# MKM34Z7 register map
Vendor: Freescale Semiconductor, Inc.; Series: Kinetis_M; File version: 1.6
CPU: CM0PLUS r0p0, little endian, no MPU, no FPU, VTOR, 2 interrupt priority bits
Registers are 32-bit, read-write, reset 0x0 unless marked. A register's access mark holds for its fields unless they carry their own. Offsets are from the block's base; [hi:lo] are bit positions; {n}, {i} and the like mark numbered series.

## NVIC — Nested Vectored Interrupt Controller
Base 0xE000E100
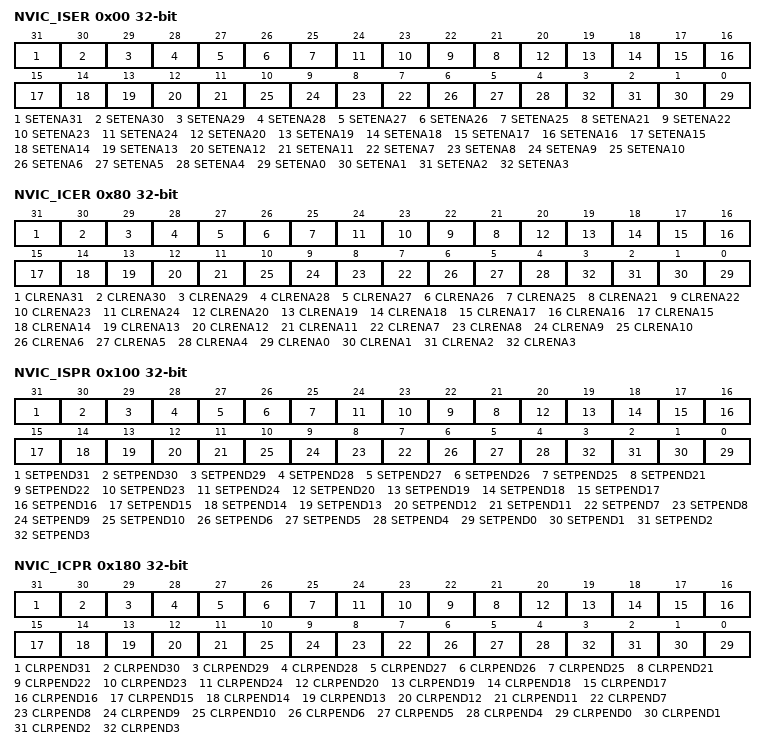
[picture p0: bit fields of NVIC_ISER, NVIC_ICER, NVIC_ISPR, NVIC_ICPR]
0x00 NVIC_ISER — Interrupt Set Enable Register
  [31] SETENA31 — XBAR interrupt set-enable bit
    0=write: no effect; read: XBAR interrupt disabled; 1=write: enable XBAR interrupt; read: XBAR interrupt enabled
  [30] SETENA30 — Low-Power Timer interrupt set-enable bit
    0=write: no effect; read: Low-Power Timer interrupt disabled; 1=write: enable Low-Power Timer interrupt; read: Low-Power Timer interrupt enabled
  [29] SETENA29 — EWM/WDOG interrupt set-enable bit
    0=write: no effect; read: EWM/WDOG interrupt disabled; 1=write: enable EWM/WDOG interrupt; read: EWM/WDOG interrupt enabled
  [28] SETENA28 — Multipurpose Clock Generator interrupt set-enable bit
    0=write: no effect; read: Multipurpose Clock Generator interrupt disabled; 1=write: enable Multipurpose Clock Generator interrupt; read: Multipurpose Clock Generator interrupt enabled
  [27] SETENA27 — LPUART0 status and error interrupt set-enable bit
    0=write: no effect; read: LPUART0 status and error interrupt disabled; 1=write: enable LPUART0 status and error interrupt; read: LPUART0 status and error interrupt enabled
  [26] SETENA26 — I2C0/I2C1 interrupt set-enable bit
    0=write: no effect; read: I2C0/I2C1 interrupt disabled; 1=write: enable I2C0/I2C1 interrupt; read: I2C0/I2C1 interrupt enabled
  [25] SETENA25 — IRTC interrupt interrupt set-enable bit
    0=write: no effect; read: IRTC interrupt interrupt disabled; 1=write: enable IRTC interrupt interrupt; read: IRTC interrupt interrupt enabled
  [n] SETENA{n} (n=21..24) — AFE Channel {n-21} interrupt set-enable bit
    0=write: no effect; read: AFE Channel {n-21} interrupt disabled; 1=write: enable AFE Channel {n-21} interrupt; read: AFE Channel {n-21} interrupt enabled
  [20] SETENA20 — Memory Mapped Arithmetic Unit interrupt set-enable bit
    0=write: no effect; read: Memory Mapped Arithmetic Unit interrupt disabled; 1=write: enable Memory Mapped Arithmetic Unit interrupt; read: Memory Mapped Arithmetic Unit interrupt enabled
  [19] SETENA19 — UART0/UART1/UART2/UART3 interrupt set-enable bit
    0=write: no effect; read: UART0/UART1/UART2/UART3 interrupt disabled; 1=write: enable UART0/UART1/UART2/UART3 interrupt; read: UART0/UART1/UART2/UART3 interrupt enabled
  [18] SETENA18 — RNGA interrupt set-enable bit
    0=write: no effect; read: RNGA interrupt disabled; 1=write: enable RNGA interrupt; read: RNGA interrupt enabled
  [17] SETENA17 — PORTA,PORTB,PORTC,PORTD,PORTE,PORTF,PORTH,PORTI,PORTJ,PORTK,PORTL,PORTM interrupt set-enable bit
    0=write: no effect; read: PORTA,PORTB,PORTC,PORTD,PORTE,PORTF,PORTH,PORTI,PORTJ,PORTK,PORTL,PORTM interrupt disabled; 1=write: enable PORTA,PORTB,PORTC,PORTD,PORTE,PORTF,PORTH,PORTI,PORTJ,PORTK,PORTL,PORTM interrupt; read: PORTA,PORTB,PORTC,PORTD,PORTE,PORTF,PORTH,PORTI,PORTJ,PORTK,PORTL,PORTM interrupt enabled
  [16] SETENA16 — Analog-to-Digital Converter interrupt set-enable bit
    0=write: no effect; read: Analog-to-Digital Converter interrupt disabled; 1=write: enable Analog-to-Digital Converter interrupt; read: Analog-to-Digital Converter interrupt enabled
  [15] SETENA15 — Segment LCD interrupt set-enable bit
    0=write: no effect; read: Segment LCD interrupt disabled; 1=write: enable Segment LCD interrupt; read: Segment LCD interrupt enabled
  [14] SETENA14 — CMP0/CMP1/CMP2 interrupt set-enable bit
    0=write: no effect; read: CMP0/CMP1/CMP2 interrupt disabled; 1=write: enable CMP0/CMP1/CMP2 interrupt; read: CMP0/CMP1/CMP2 interrupt enabled
  [13] SETENA13 — Command complete and read collision interrupt set-enable bit
    0=write: no effect; read: Command complete and read collision interrupt disabled; 1=write: enable Command complete and read collision interrupt; read: Command complete and read collision interrupt enabled
  [12] SETENA12 — Low Leakage Wakeup interrupt set-enable bit
    0=write: no effect; read: Low Leakage Wakeup interrupt disabled; 1=write: enable Low Leakage Wakeup interrupt; read: Low Leakage Wakeup interrupt enabled
  [11] SETENA11 — PIT0/PIT1 interrupt set-enable bit
    0=write: no effect; read: PIT0/PIT1 interrupt disabled; 1=write: enable PIT0/PIT1 interrupt; read: PIT0/PIT1 interrupt enabled
  [n] SETENA{n} (n=7..10) — Quad Timer Channel {n-7} interrupt set-enable bit
    0=write: no effect; read: Quad Timer Channel {n-7} interrupt disabled; 1=write: enable Quad Timer Channel {n-7} interrupt; read: Quad Timer Channel {n-7} interrupt enabled
  [6] SETENA6 — Low-voltage detect, low-voltage warning interrupt set-enable bit
    0=write: no effect; read: Low-voltage detect, low-voltage warning interrupt disabled; 1=write: enable Low-voltage detect, low-voltage warning interrupt; read: Low-voltage detect, low-voltage warning interrupt enabled
  [5] SETENA5 — Programmable Delay Block 0 interrupt set-enable bit
    0=write: no effect; read: Programmable Delay Block 0 interrupt disabled; 1=write: enable Programmable Delay Block 0 interrupt; read: Programmable Delay Block 0 interrupt enabled
  [4] SETENA4 — Serial Peripheral Interface 0/1 interrupt set-enable bit
    0=write: no effect; read: Serial Peripheral Interface 0/1 interrupt disabled; 1=write: enable Serial Peripheral Interface 0/1 interrupt; read: Serial Peripheral Interface 0/1 interrupt enabled
  [n] SETENA{n} (n=0..3) — DMA channel {n} transfer complete interrupt set-enable bit
    0=write: no effect; read: DMA channel {n} transfer complete interrupt disabled; 1=write: enable DMA channel {n} transfer complete interrupt; read: DMA channel {n} transfer complete interrupt enabled
0x80 NVIC_ICER — Interrupt Clear Enable Register
  [31] CLRENA31 — XBAR interrupt clear-enable bit
    0=write: no effect; read: XBAR interrupt disabled; 1=write: disable XBAR interrupt; read: XBAR interrupt enabled
  [30] CLRENA30 — Low-Power Timer interrupt clear-enable bit
    0=write: no effect; read: Low-Power Timer interrupt disabled; 1=write: disable Low-Power Timer interrupt; read: Low-Power Timer interrupt enabled
  [29] CLRENA29 — EWM/WDOG interrupt clear-enable bit
    0=write: no effect; read: EWM/WDOG interrupt disabled; 1=write: disable EWM/WDOG interrupt; read: EWM/WDOG interrupt enabled
  [28] CLRENA28 — Multipurpose Clock Generator interrupt clear-enable bit
    0=write: no effect; read: Multipurpose Clock Generator interrupt disabled; 1=write: disable Multipurpose Clock Generator interrupt; read: Multipurpose Clock Generator interrupt enabled
  [27] CLRENA27 — LPUART0 status and error interrupt clear-enable bit
    0=write: no effect; read: LPUART0 status and error interrupt disabled; 1=write: disable LPUART0 status and error interrupt; read: LPUART0 status and error interrupt enabled
  [26] CLRENA26 — I2C0/I2C1 interrupt clear-enable bit
    0=write: no effect; read: I2C0/I2C1 interrupt disabled; 1=write: disable I2C0/I2C1 interrupt; read: I2C0/I2C1 interrupt enabled
  [25] CLRENA25 — IRTC interrupt interrupt clear-enable bit
    0=write: no effect; read: IRTC interrupt interrupt disabled; 1=write: disable IRTC interrupt interrupt; read: IRTC interrupt interrupt enabled
  [n] CLRENA{n} (n=21..24) — AFE Channel {n-21} interrupt clear-enable bit
    0=write: no effect; read: AFE Channel {n-21} interrupt disabled; 1=write: disable AFE Channel {n-21} interrupt; read: AFE Channel {n-21} interrupt enabled
  [20] CLRENA20 — Memory Mapped Arithmetic Unit interrupt clear-enable bit
    0=write: no effect; read: Memory Mapped Arithmetic Unit interrupt disabled; 1=write: disable Memory Mapped Arithmetic Unit interrupt; read: Memory Mapped Arithmetic Unit interrupt enabled
  [19] CLRENA19 — UART0/UART1/UART2/UART3 interrupt clear-enable bit
    0=write: no effect; read: UART0/UART1/UART2/UART3 interrupt disabled; 1=write: disable UART0/UART1/UART2/UART3 interrupt; read: UART0/UART1/UART2/UART3 interrupt enabled
  [18] CLRENA18 — RNGA interrupt clear-enable bit
    0=write: no effect; read: RNGA interrupt disabled; 1=write: disable RNGA interrupt; read: RNGA interrupt enabled
  [17] CLRENA17 — PORTA,PORTB,PORTC,PORTD,PORTE,PORTF,PORTH,PORTI,PORTJ,PORTK,PORTL,PORTM interrupt clear-enable bit
    0=write: no effect; read: PORTA,PORTB,PORTC,PORTD,PORTE,PORTF,PORTH,PORTI,PORTJ,PORTK,PORTL,PORTM interrupt disabled; 1=write: disable PORTA,PORTB,PORTC,PORTD,PORTE,PORTF,PORTH,PORTI,PORTJ,PORTK,PORTL,PORTM interrupt; read: PORTA,PORTB,PORTC,PORTD,PORTE,PORTF,PORTH,PORTI,PORTJ,PORTK,PORTL,PORTM interrupt enabled
  [16] CLRENA16 — Analog-to-Digital Converter interrupt clear-enable bit
    0=write: no effect; read: Analog-to-Digital Converter interrupt disabled; 1=write: disable Analog-to-Digital Converter interrupt; read: Analog-to-Digital Converter interrupt enabled
  [15] CLRENA15 — Segment LCD interrupt clear-enable bit
    0=write: no effect; read: Segment LCD interrupt disabled; 1=write: disable Segment LCD interrupt; read: Segment LCD interrupt enabled
  [14] CLRENA14 — CMP0/CMP1/CMP2 interrupt clear-enable bit
    0=write: no effect; read: CMP0/CMP1/CMP2 interrupt disabled; 1=write: disable CMP0/CMP1/CMP2 interrupt; read: CMP0/CMP1/CMP2 interrupt enabled
  [13] CLRENA13 — Command complete and read collision interrupt clear-enable bit
    0=write: no effect; read: Command complete and read collision interrupt disabled; 1=write: disable Command complete and read collision interrupt; read: Command complete and read collision interrupt enabled
  [12] CLRENA12 — Low Leakage Wakeup interrupt clear-enable bit
    0=write: no effect; read: Low Leakage Wakeup interrupt disabled; 1=write: disable Low Leakage Wakeup interrupt; read: Low Leakage Wakeup interrupt enabled
  [11] CLRENA11 — PIT0/PIT1 interrupt clear-enable bit
    0=write: no effect; read: PIT0/PIT1 interrupt disabled; 1=write: disable PIT0/PIT1 interrupt; read: PIT0/PIT1 interrupt enabled
  [n] CLRENA{n} (n=7..10) — Quad Timer Channel {n-7} interrupt clear-enable bit
    0=write: no effect; read: Quad Timer Channel {n-7} interrupt disabled; 1=write: disable Quad Timer Channel {n-7} interrupt; read: Quad Timer Channel {n-7} interrupt enabled
  [6] CLRENA6 — Low-voltage detect, low-voltage warning interrupt clear-enable bit
    0=write: no effect; read: Low-voltage detect, low-voltage warning interrupt disabled; 1=write: disable Low-voltage detect, low-voltage warning interrupt; read: Low-voltage detect, low-voltage warning interrupt enabled
  [5] CLRENA5 — Programmable Delay Block 0 interrupt clear-enable bit
    0=write: no effect; read: Programmable Delay Block 0 interrupt disabled; 1=write: disable Programmable Delay Block 0 interrupt; read: Programmable Delay Block 0 interrupt enabled
  [4] CLRENA4 — Serial Peripheral Interface 0/1 interrupt clear-enable bit
    0=write: no effect; read: Serial Peripheral Interface 0/1 interrupt disabled; 1=write: disable Serial Peripheral Interface 0/1 interrupt; read: Serial Peripheral Interface 0/1 interrupt enabled
  [n] CLRENA{n} (n=0..3) — DMA channel {n} transfer complete interrupt clear-enable bit
    0=write: no effect; read: DMA channel {n} transfer complete interrupt disabled; 1=write: disable DMA channel {n} transfer complete interrupt; read: DMA channel {n} transfer complete interrupt enabled
0x100 NVIC_ISPR — Interrupt Set Pending Register
  [31] SETPEND31 — XBAR interrupt set-pending bit
    0=write: no effect; read: XBAR interrupt is not pending; 1=write: changes the XBAR interrupt state to pending; read: XBAR interrupt is pending
  [30] SETPEND30 — Low-Power Timer interrupt set-pending bit
    0=write: no effect; read: Low-Power Timer interrupt is not pending; 1=write: changes the Low-Power Timer interrupt state to pending; read: Low-Power Timer interrupt is pending
  [29] SETPEND29 — EWM/WDOG interrupt set-pending bit
    0=write: no effect; read: EWM/WDOG interrupt is not pending; 1=write: changes the EWM/WDOG interrupt state to pending; read: EWM/WDOG interrupt is pending
  [28] SETPEND28 — Multipurpose Clock Generator interrupt set-pending bit
    0=write: no effect; read: Multipurpose Clock Generator interrupt is not pending; 1=write: changes the Multipurpose Clock Generator interrupt state to pending; read: Multipurpose Clock Generator interrupt is pending
  [27] SETPEND27 — LPUART0 status and error interrupt set-pending bit
    0=write: no effect; read: LPUART0 status and error interrupt is not pending; 1=write: changes the LPUART0 status and error interrupt state to pending; read: LPUART0 status and error interrupt is pending
  [26] SETPEND26 — I2C0/I2C1 interrupt set-pending bit
    0=write: no effect; read: I2C0/I2C1 interrupt is not pending; 1=write: changes the I2C0/I2C1 interrupt state to pending; read: I2C0/I2C1 interrupt is pending
  [25] SETPEND25 — IRTC interrupt interrupt set-pending bit
    0=write: no effect; read: IRTC interrupt interrupt is not pending; 1=write: changes the IRTC interrupt interrupt state to pending; read: IRTC interrupt interrupt is pending
  [n] SETPEND{n} (n=21..24) — AFE Channel {n-21} interrupt set-pending bit
    0=write: no effect; read: AFE Channel {n-21} interrupt is not pending; 1=write: changes the AFE Channel {n-21} interrupt state to pending; read: AFE Channel {n-21} interrupt is pending
  [20] SETPEND20 — Memory Mapped Arithmetic Unit interrupt set-pending bit
    0=write: no effect; read: Memory Mapped Arithmetic Unit interrupt is not pending; 1=write: changes the Memory Mapped Arithmetic Unit interrupt state to pending; read: Memory Mapped Arithmetic Unit interrupt is pending
  [19] SETPEND19 — UART0/UART1/UART2/UART3 interrupt set-pending bit
    0=write: no effect; read: UART0/UART1/UART2/UART3 interrupt is not pending; 1=write: changes the UART0/UART1/UART2/UART3 interrupt state to pending; read: UART0/UART1/UART2/UART3 interrupt is pending
  [18] SETPEND18 — RNGA interrupt set-pending bit
    0=write: no effect; read: RNGA interrupt is not pending; 1=write: changes the RNGA interrupt state to pending; read: RNGA interrupt is pending
  [17] SETPEND17 — PORTA,PORTB,PORTC,PORTD,PORTE,PORTF,PORTH,PORTI,PORTJ,PORTK,PORTL,PORTM interrupt set-pending bit
    0=write: no effect; read: PORTA,PORTB,PORTC,PORTD,PORTE,PORTF,PORTH,PORTI,PORTJ,PORTK,PORTL,PORTM interrupt is not pending; 1=write: changes the PORTA,PORTB,PORTC,PORTD,PORTE,PORTF,PORTH,PORTI,PORTJ,PORTK,PORTL,PORTM interrupt state to pending; read: PORTA,PORTB,PORTC,PORTD,PORTE,PORTF,PORTH,PORTI,PORTJ,PORTK,PORTL,PORTM interrupt is pending
  [16] SETPEND16 — Analog-to-Digital Converter interrupt set-pending bit
    0=write: no effect; read: Analog-to-Digital Converter interrupt is not pending; 1=write: changes the Analog-to-Digital Converter interrupt state to pending; read: Analog-to-Digital Converter interrupt is pending
  [15] SETPEND15 — Segment LCD interrupt set-pending bit
    0=write: no effect; read: Segment LCD interrupt is not pending; 1=write: changes the Segment LCD interrupt state to pending; read: Segment LCD interrupt is pending
  [14] SETPEND14 — CMP0/CMP1/CMP2 interrupt set-pending bit
    0=write: no effect; read: CMP0/CMP1/CMP2 interrupt is not pending; 1=write: changes the CMP0/CMP1/CMP2 interrupt state to pending; read: CMP0/CMP1/CMP2 interrupt is pending
  [13] SETPEND13 — Command complete and read collision interrupt set-pending bit
    0=write: no effect; read: Command complete and read collision interrupt is not pending; 1=write: changes the Command complete and read collision interrupt state to pending; read: Command complete and read collision interrupt is pending
  [12] SETPEND12 — Low Leakage Wakeup interrupt set-pending bit
    0=write: no effect; read: Low Leakage Wakeup interrupt is not pending; 1=write: changes the Low Leakage Wakeup interrupt state to pending; read: Low Leakage Wakeup interrupt is pending
  [11] SETPEND11 — PIT0/PIT1 interrupt set-pending bit
    0=write: no effect; read: PIT0/PIT1 interrupt is not pending; 1=write: changes the PIT0/PIT1 interrupt state to pending; read: PIT0/PIT1 interrupt is pending
  [n] SETPEND{n} (n=7..10) — Quad Timer Channel {n-7} interrupt set-pending bit
    0=write: no effect; read: Quad Timer Channel {n-7} interrupt is not pending; 1=write: changes the Quad Timer Channel {n-7} interrupt state to pending; read: Quad Timer Channel {n-7} interrupt is pending
  [6] SETPEND6 — Low-voltage detect, low-voltage warning interrupt set-pending bit
    0=write: no effect; read: Low-voltage detect, low-voltage warning interrupt is not pending; 1=write: changes the Low-voltage detect, low-voltage warning interrupt state to pending; read: Low-voltage detect, low-voltage warning interrupt is pending
  [5] SETPEND5 — Programmable Delay Block 0 interrupt set-pending bit
    0=write: no effect; read: Programmable Delay Block 0 interrupt is not pending; 1=write: changes the Programmable Delay Block 0 interrupt state to pending; read: Programmable Delay Block 0 interrupt is pending
  [4] SETPEND4 — Serial Peripheral Interface 0/1 interrupt set-pending bit
    0=write: no effect; read: Serial Peripheral Interface 0/1 interrupt is not pending; 1=write: changes the Serial Peripheral Interface 0/1 interrupt state to pending; read: Serial Peripheral Interface 0/1 interrupt is pending
  [n] SETPEND{n} (n=0..3) — DMA channel {n} transfer complete interrupt set-pending bit
    0=write: no effect; read: DMA channel {n} transfer complete interrupt is not pending; 1=write: changes the DMA channel {n} transfer complete interrupt state to pending; read: DMA channel {n} transfer complete interrupt is pending
0x180 NVIC_ICPR — Interrupt Clear Pending Register
  [31] CLRPEND31 — XBAR interrupt clear-pending bit
    0=write: no effect; read: XBAR interrupt is not pending; 1=write: removes pending state from the XBAR interrupt; read: XBAR interrupt is pending
  [30] CLRPEND30 — Low-Power Timer interrupt clear-pending bit
    0=write: no effect; read: Low-Power Timer interrupt is not pending; 1=write: removes pending state from the Low-Power Timer interrupt; read: Low-Power Timer interrupt is pending
  [29] CLRPEND29 — EWM/WDOG interrupt clear-pending bit
    0=write: no effect; read: EWM/WDOG interrupt is not pending; 1=write: removes pending state from the EWM/WDOG interrupt; read: EWM/WDOG interrupt is pending
  [28] CLRPEND28 — Multipurpose Clock Generator interrupt clear-pending bit
    0=write: no effect; read: Multipurpose Clock Generator interrupt is not pending; 1=write: removes pending state from the Multipurpose Clock Generator interrupt; read: Multipurpose Clock Generator interrupt is pending
  [27] CLRPEND27 — LPUART0 status and error interrupt clear-pending bit
    0=write: no effect; read: LPUART0 status and error interrupt is not pending; 1=write: removes pending state from the LPUART0 status and error interrupt; read: LPUART0 status and error interrupt is pending
  [26] CLRPEND26 — I2C0/I2C1 interrupt clear-pending bit
    0=write: no effect; read: I2C0/I2C1 interrupt is not pending; 1=write: removes pending state from the I2C0/I2C1 interrupt; read: I2C0/I2C1 interrupt is pending
  [25] CLRPEND25 — IRTC interrupt interrupt clear-pending bit
    0=write: no effect; read: IRTC interrupt interrupt is not pending; 1=write: removes pending state from the IRTC interrupt interrupt; read: IRTC interrupt interrupt is pending
  [n] CLRPEND{n} (n=21..24) — AFE Channel {n-21} interrupt clear-pending bit
    0=write: no effect; read: AFE Channel {n-21} interrupt is not pending; 1=write: removes pending state from the AFE Channel {n-21} interrupt; read: AFE Channel {n-21} interrupt is pending
  [20] CLRPEND20 — Memory Mapped Arithmetic Unit interrupt clear-pending bit
    0=write: no effect; read: Memory Mapped Arithmetic Unit interrupt is not pending; 1=write: removes pending state from the Memory Mapped Arithmetic Unit interrupt; read: Memory Mapped Arithmetic Unit interrupt is pending
  [19] CLRPEND19 — UART0/UART1/UART2/UART3 interrupt clear-pending bit
    0=write: no effect; read: UART0/UART1/UART2/UART3 interrupt is not pending; 1=write: removes pending state from the UART0/UART1/UART2/UART3 interrupt; read: UART0/UART1/UART2/UART3 interrupt is pending
  [18] CLRPEND18 — RNGA interrupt clear-pending bit
    0=write: no effect; read: RNGA interrupt is not pending; 1=write: removes pending state from the RNGA interrupt; read: RNGA interrupt is pending
  [17] CLRPEND17 — PORTA,PORTB,PORTC,PORTD,PORTE,PORTF,PORTH,PORTI,PORTJ,PORTK,PORTL,PORTM interrupt clear-pending bit
    0=write: no effect; read: PORTA,PORTB,PORTC,PORTD,PORTE,PORTF,PORTH,PORTI,PORTJ,PORTK,PORTL,PORTM interrupt is not pending; 1=write: removes pending state from the PORTA,PORTB,PORTC,PORTD,PORTE,PORTF,PORTH,PORTI,PORTJ,PORTK,PORTL,PORTM interrupt; read: PORTA,PORTB,PORTC,PORTD,PORTE,PORTF,PORTH,PORTI,PORTJ,PORTK,PORTL,PORTM interrupt is pending
  [16] CLRPEND16 — Analog-to-Digital Converter interrupt clear-pending bit
    0=write: no effect; read: Analog-to-Digital Converter interrupt is not pending; 1=write: removes pending state from the Analog-to-Digital Converter interrupt; read: Analog-to-Digital Converter interrupt is pending
  [15] CLRPEND15 — Segment LCD interrupt clear-pending bit
    0=write: no effect; read: Segment LCD interrupt is not pending; 1=write: removes pending state from the Segment LCD interrupt; read: Segment LCD interrupt is pending
  [14] CLRPEND14 — CMP0/CMP1/CMP2 interrupt clear-pending bit
    0=write: no effect; read: CMP0/CMP1/CMP2 interrupt is not pending; 1=write: removes pending state from the CMP0/CMP1/CMP2 interrupt; read: CMP0/CMP1/CMP2 interrupt is pending
  [13] CLRPEND13 — Command complete and read collision interrupt clear-pending bit
    0=write: no effect; read: Command complete and read collision interrupt is not pending; 1=write: removes pending state from the Command complete and read collision interrupt; read: Command complete and read collision interrupt is pending
  [12] CLRPEND12 — Low Leakage Wakeup interrupt clear-pending bit
    0=write: no effect; read: Low Leakage Wakeup interrupt is not pending; 1=write: removes pending state from the Low Leakage Wakeup interrupt; read: Low Leakage Wakeup interrupt is pending
  [11] CLRPEND11 — PIT0/PIT1 interrupt clear-pending bit
    0=write: no effect; read: PIT0/PIT1 interrupt is not pending; 1=write: removes pending state from the PIT0/PIT1 interrupt; read: PIT0/PIT1 interrupt is pending
  [n] CLRPEND{n} (n=7..10) — Quad Timer Channel {n-7} interrupt clear-pending bit
    0=write: no effect; read: Quad Timer Channel {n-7} interrupt is not pending; 1=write: removes pending state from the Quad Timer Channel {n-7} interrupt; read: Quad Timer Channel {n-7} interrupt is pending
  [6] CLRPEND6 — Low-voltage detect, low-voltage warning interrupt clear-pending bit
    0=write: no effect; read: Low-voltage detect, low-voltage warning interrupt is not pending; 1=write: removes pending state from the Low-voltage detect, low-voltage warning interrupt; read: Low-voltage detect, low-voltage warning interrupt is pending
  [5] CLRPEND5 — Programmable Delay Block 0 interrupt clear-pending bit
    0=write: no effect; read: Programmable Delay Block 0 interrupt is not pending; 1=write: removes pending state from the Programmable Delay Block 0 interrupt; read: Programmable Delay Block 0 interrupt is pending
  [4] CLRPEND4 — Serial Peripheral Interface 0/1 interrupt clear-pending bit
    0=write: no effect; read: Serial Peripheral Interface 0/1 interrupt is not pending; 1=write: removes pending state from the Serial Peripheral Interface 0/1 interrupt; read: Serial Peripheral Interface 0/1 interrupt is pending
  [n] CLRPEND{n} (n=0..3) — DMA channel {n} transfer complete interrupt clear-pending bit
    0=write: no effect; read: DMA channel {n} transfer complete interrupt is not pending; 1=write: removes pending state from the DMA channel {n} transfer complete interrupt; read: DMA channel {n} transfer complete interrupt is pending
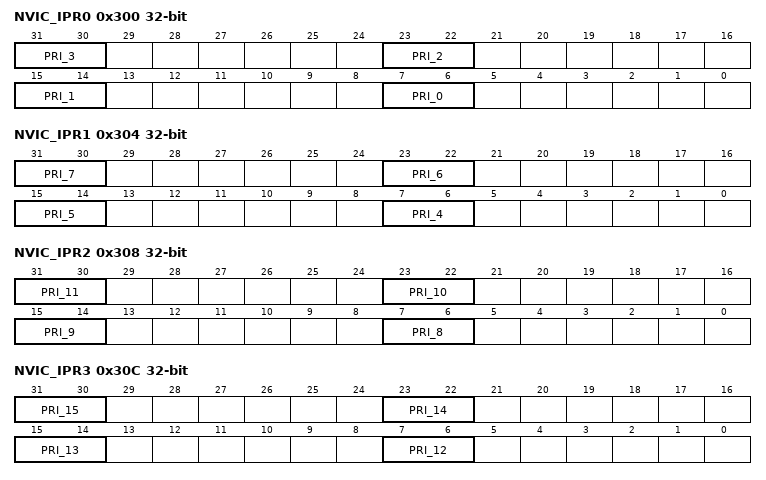
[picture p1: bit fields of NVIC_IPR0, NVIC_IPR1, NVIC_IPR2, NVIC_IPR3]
0x300 NVIC_IPR0 — Interrupt Priority Register 0
  [8n+7:8n+6] PRI_{n} (n=0..3) — Priority of the DMA channel {n} transfer complete interrupt
0x304 NVIC_IPR1 — Interrupt Priority Register 1
  [31:30] PRI_7 — Priority of the Quad Timer Channel 0 interrupt
  [23:22] PRI_6 — Priority of the Low-voltage detect, low-voltage warning interrupt
  [15:14] PRI_5 — Priority of the Programmable Delay Block 0 interrupt
  [7:6] PRI_4 — Priority of the Serial Peripheral Interface 0/1 interrupt
0x308 NVIC_IPR2 — Interrupt Priority Register 2
  [31:30] PRI_11 — Priority of the PIT0/PIT1 interrupt
  [23:22] PRI_10 — Priority of the Quad Timer Channel 3 interrupt
  [15:14] PRI_9 — Priority of the Quad Timer Channel 2 interrupt
  [7:6] PRI_8 — Priority of the Quad Timer Channel 1 interrupt
0x30C NVIC_IPR3 — Interrupt Priority Register 3
  [31:30] PRI_15 — Priority of the Segment LCD interrupt
  [23:22] PRI_14 — Priority of the CMP0/CMP1/CMP2 interrupt
  [15:14] PRI_13 — Priority of the Command complete and read collision interrupt
  [7:6] PRI_12 — Priority of the Low Leakage Wakeup interrupt
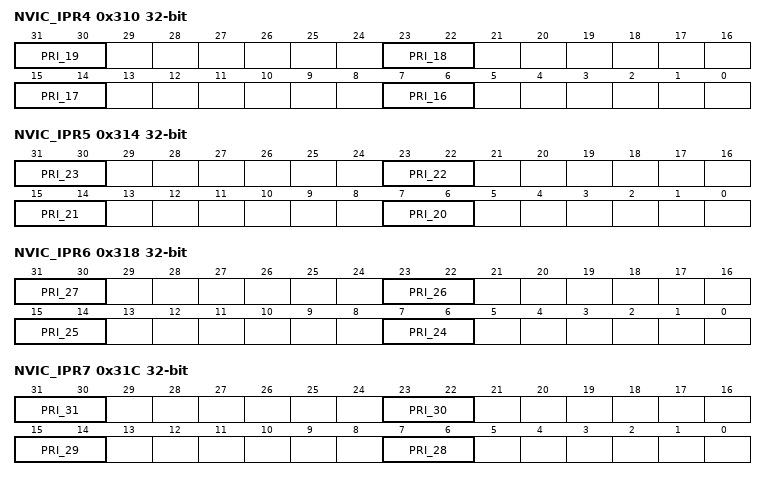
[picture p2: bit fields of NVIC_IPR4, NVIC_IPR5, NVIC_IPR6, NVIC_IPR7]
0x310 NVIC_IPR4 — Interrupt Priority Register 4
  [31:30] PRI_19 — Priority of the UART0/UART1/UART2/UART3 interrupt
  [23:22] PRI_18 — Priority of the RNGA interrupt
  [15:14] PRI_17 — Priority of the PORTA,PORTB,PORTC,PORTD,PORTE,PORTF,PORTH,PORTI,PORTJ,PORTK,PORTL,PORTM interrupt
  [7:6] PRI_16 — Priority of the Analog-to-Digital Converter interrupt
0x314 NVIC_IPR5 — Interrupt Priority Register 5
  [31:30] PRI_23 — Priority of the AFE Channel 2 interrupt
  [23:22] PRI_22 — Priority of the AFE Channel 1 interrupt
  [15:14] PRI_21 — Priority of the AFE Channel 0 interrupt
  [7:6] PRI_20 — Priority of the Memory Mapped Arithmetic Unit interrupt
0x318 NVIC_IPR6 — Interrupt Priority Register 6
  [31:30] PRI_27 — Priority of the LPUART0 status and error interrupt
  [23:22] PRI_26 — Priority of the I2C0/I2C1 interrupt
  [15:14] PRI_25 — Priority of the IRTC interrupt interrupt
  [7:6] PRI_24 — Priority of the AFE Channel 3 interrupt
0x31C NVIC_IPR7 — Interrupt Priority Register 7
  [31:30] PRI_31 — Priority of the XBAR interrupt
  [23:22] PRI_30 — Priority of the Low-Power Timer interrupt
  [15:14] PRI_29 — Priority of the EWM/WDOG interrupt
  [7:6] PRI_28 — Priority of the Multipurpose Clock Generator interrupt
